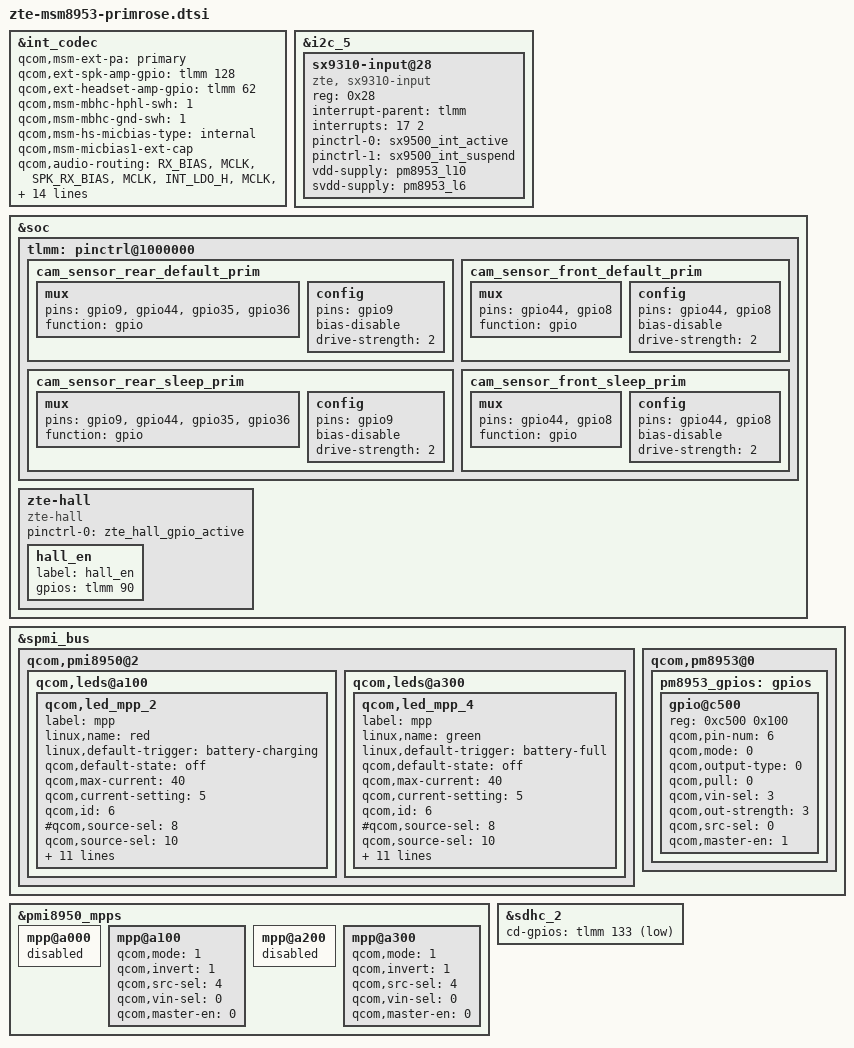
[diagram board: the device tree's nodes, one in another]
/*
 * device tree for zte primrose board
 */
#include "touch-key-backlight-primrose.dtsi"

&int_codec {
	qcom,msm-ext-pa = "primary";
	qcom,ext-spk-amp-gpio = <&tlmm 128 0>;
	qcom,ext-headset-amp-gpio = <&tlmm 62 0>;
	qcom,msm-mbhc-hphl-swh = <1>;
	qcom,msm-mbhc-gnd-swh = <1>;
	qcom,msm-hs-micbias-type = "internal";
	qcom,msm-micbias1-ext-cap;

	qcom,audio-routing =
		"RX_BIAS", "MCLK",
		"SPK_RX_BIAS", "MCLK",
		"INT_LDO_H", "MCLK",
		"MIC BIAS External", "Handset Mic",
		"MIC BIAS Internal2", "Headset Mic",
		"MIC BIAS External", "Secondary Mic",
		"AMIC1", "MIC BIAS External",
		"AMIC2", "MIC BIAS Internal2",
		"AMIC3", "MIC BIAS External",
		"Lineout_hph amp", "HEADPHONE",
		"WSA_SPK OUT", "VDD_WSA_SWITCH",
		"SpkrMono WSA_IN", "WSA_SPK OUT";
	qcom,msm-gpios =
			"pri_i2s";
	qcom,pinctrl-names =
			"all_off",
			"pri_i2s_act";
	pinctrl-names =
			"all_off",
			"pri_i2s_act";
	pinctrl-0 = <&cdc_pdm_lines_sus &cdc_pdm_lines_2_sus >;
	pinctrl-1 = <&cdc_pdm_lines_act &cdc_pdm_lines_2_act >;

};

&i2c_5 { // BLSP2 QUP1
	sx9310-input@28 {
		compatible = "zte, sx9310-input";
		reg = <0x28>;
		//cc,irq_gpio = <&tlmm 17 0x0>;
		interrupt-parent = <&tlmm>;
		interrupts = <17 2>;
		interrupt-names = "sx9310_irq";
		pinctrl-names = "sx9310_active", "sx9310_sleep";
		pinctrl-0 = <&sx9500_int_active>;
		pinctrl-1 = <&sx9500_int_suspend >;
		vdd-supply = <&pm8953_l10>;
		svdd-supply = <&pm8953_l6>;
	};
};

&soc {
	tlmm: pinctrl@1000000 {
		cam_sensor_rear_default_prim: cam_sensor_rear_default_prim {
			/* RESET, STANDBY */
			mux {
				pins = "gpio9", "gpio44", "gpio35", "gpio36";
				function = "gpio";
			};

			config {
				pins = "gpio9";
				bias-disable; /* No PULL */
				drive-strength = <2>; /* 2 MA */
			};
		};

		cam_sensor_rear_sleep_prim: cam_sensor_rear_sleep_prim {
			/* RESET, STANDBY */
			mux {
				pins = "gpio9", "gpio44", "gpio35", "gpio36";
				function = "gpio";
			};

			config {
				pins = "gpio9";
				bias-disable; /* No PULL */
				drive-strength = <2>; /* 2 MA */
			};
		};

		cam_sensor_front_default_prim: cam_sensor_front_default_prim {
			/* RESET, STANDBY */
			mux {
				pins = "gpio44","gpio8";
				function = "gpio";
			};

			config {
				pins = "gpio44","gpio8";
				bias-disable; /* No PULL */
				drive-strength = <2>; /* 2 MA */
			};
		};

		cam_sensor_front_sleep_prim: cam_sensor_front_sleep_prim {
			/* RESET, STANDBY */
			mux {
				pins = "gpio44","gpio8";
				function = "gpio";
			};

			config {
				pins = "gpio44","gpio8";
				bias-disable; /* No PULL */
				drive-strength = <2>; /* 2 MA */
			};
		};
	};
	zte-hall {
		compatible = "zte-hall";
		pinctrl-names = "zte_hall_gpio_active";
		pinctrl-0 = <&zte_hall_gpio_active>;
		hall_en{
			label = "hall_en";
			gpios = <&tlmm 90 0x0>;
		};
	};
};

&spmi_bus {

	qcom,pmi8950@2 {
		qcom,leds@a100 {
			status = "okay";
			qcom,led_mpp_2 {	/* red led */
				label = "mpp";
				linux,name = "red";
				linux,default-trigger = "battery-charging";
				qcom,default-state = "off";
				qcom,max-current = <40>;
				qcom,current-setting = <5>;
				qcom,id = <6>;
				#qcom,source-sel = <8>;
				qcom,source-sel = <10>; /* connect MPP to DTEST2*/
				qcom,src-sel = <10>;

				qcom,mode-ctrl = <0x60>;
				qcom,pwm-channel = <0>;
				qcom,pwm-us = <1000>;
				qcom,vin-ctrl = <0x00>;
				qcom,duty-pcts = <50>;
				qcom,mode = "pwm";
				qcom,use-blink;
				pwms = <&pmi8950_pwm 0 0>;
				qcom,pwm-names = "red-led";
				zte,is-operator-sprint = "no";
			};
		};

	qcom,leds@a300 {
			status = "okay";
			qcom,led_mpp_4 {	/* green led */
				label = "mpp";
				linux,name = "green";		/* orgin is wled-backlight */
				linux,default-trigger = "battery-full";	/* org="bkl-trigger"; */
				qcom,default-state = "off";
				qcom,max-current = <40>;
				qcom,current-setting = <5>;	/*+ zte add +*/
				qcom,id = <6>;				/* in leds-qpnp.c enum QPNP_ID_LED_MPP(6) */
				#qcom,source-sel = <8>;		/* select power source, default 1 (enabled)(org=8) */
				qcom,source-sel = <10>; /* connect MPP to DTEST2*/
				qcom,src-sel = <10>;
				qcom,mode-ctrl = <0x60>;	/* operation mode, default 0x60 = Mode Sink (org=0x10)*/
				qcom,pwm-channel = <0>;
				qcom,pwm-us = <1000>;
				qcom,vin-ctrl = <0x00>;		/* select input source, 0 to 3 */
				qcom,duty-pcts = <50>;
				qcom,mode = "pwm";
				qcom,use-blink;
				pwms = <&pmi8950_pwm 0 0>;
				qcom,pwm-names = "green-led";
				zte,is-operator-sprint = "no";
			};
		};
	};
	qcom,pm8953@0 {
		pm8953_gpios: gpios {
			gpio@c500 {
				reg = <0xc500 0x100>;
				qcom,pin-num = <6>;
				qcom,mode = <0>;
				qcom,output-type = <0>;
				qcom,pull = <0>;
				qcom,vin-sel = <3>;
				qcom,out-strength = <3>;
				qcom,src-sel = <0>;
				qcom,master-en = <1>;
				//qcom,dtest-sel = <1>;
				status = "okay";
			};
		};
	};
};
&pmi8950_mpps {
	mpp@a000 { /* MPP 1 */
		/* VDD_PX */
		status = "disabled";
	};

	mpp@a100 { /* MPP 2 */
		/* Backlight PWM */
		qcom,mode = <1>;		/* Digital output */
		qcom,invert = <1>;		/* Enable invert */
		qcom,src-sel = <4>;		/* DTEST1 */
		qcom,vin-sel = <0>;		/* VPH_PWR */
		qcom,master-en = <0>;		/* Enable MPP */
	};
	mpp@a200 { /* MPP 3 */
		/* VREF DAC */
		status = "disabled";
	};

	mpp@a300 { /* MPP 4 */
		/* HR LED */
		qcom,mode = <1>;		/* Digital output */
		qcom,invert = <1>;		/* Enable invert */
		qcom,src-sel = <4>;		/* DTEST1 */
		qcom,vin-sel = <0>;		/* VPH_PWR */
		qcom,master-en = <0>;	/* Enable MPP */
	};
};
&sdhc_2 {
	cd-gpios = <&tlmm 133 0x1>;
};
